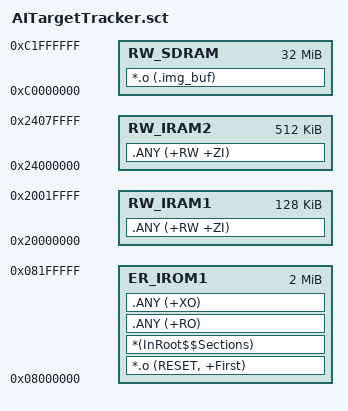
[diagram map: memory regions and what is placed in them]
; *************************************************************
; *** Scatter-Loading Description File generated by uVision ***
; *************************************************************

LR_IROM1 0x08000000 0x00200000  {    ; load region size_region
  ER_IROM1 0x08000000 0x00200000  {  ; load address = execution address
   *.o (RESET, +First)
   *(InRoot$$Sections)
   .ANY (+RO)
   .ANY (+XO)
  }
  RW_IRAM1 0x20000000 0x00020000  {  ; RW data
   .ANY (+RW +ZI)
  }
  RW_IRAM2 0x24000000 0x00080000  {
   .ANY (+RW +ZI)
  }
  ; 新增：SDRAM执行区域（外部SDRAM，用于双缓冲）
  RW_SDRAM 0xC0000000 0x02000000  {  ; 执行区域：外部SDRAM（0xC0000000~0xC1FFFFFF，32MB）
   *.o (.img_buf)  ; 仅将.img_buf段的内容（双缓冲数组）放到SDRAM
  }
}

